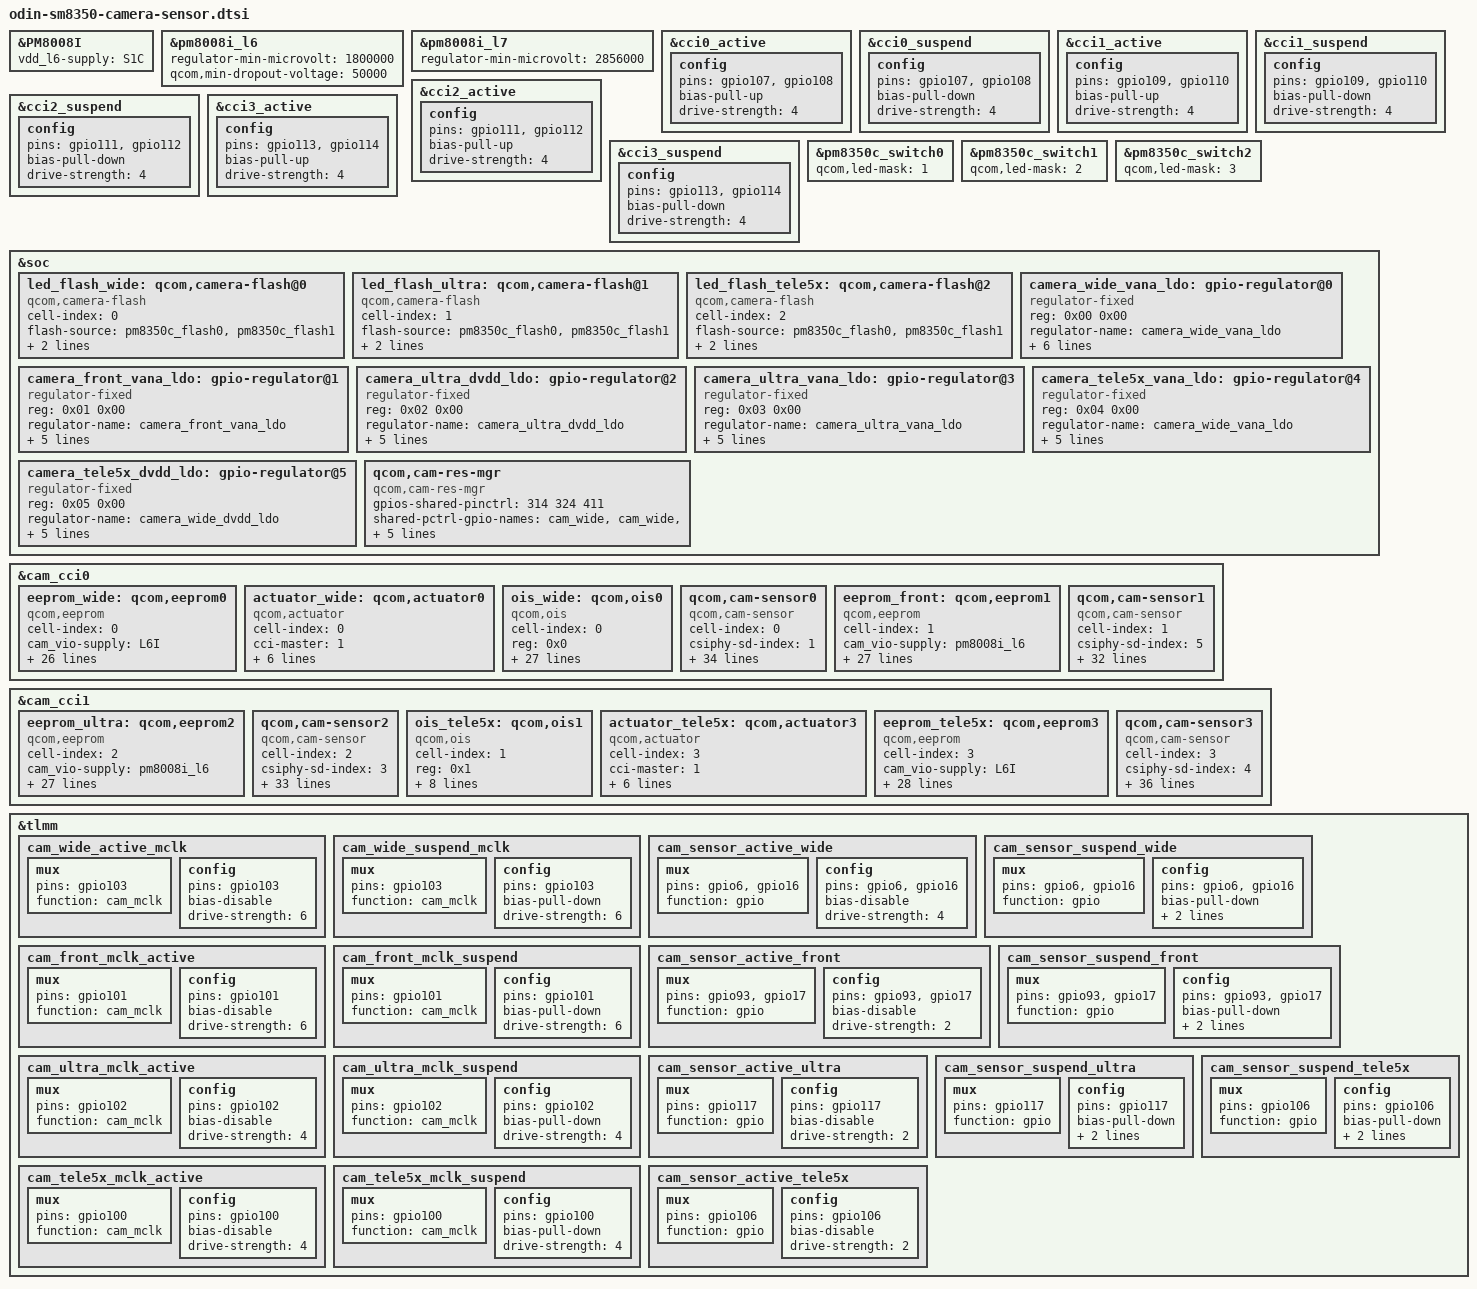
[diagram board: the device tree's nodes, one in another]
#include <dt-bindings/clock/qcom,camcc-lahaina.h>

&PM8008I {
	vdd_l6-supply = <&S1C>;
};

&pm8008i_l6 {
	regulator-min-microvolt = <1800000>;
	qcom,min-dropout-voltage = <50000>;
};

&pm8008i_l7 {
	regulator-min-microvolt = <2856000>;
};

&cci0_active {
	config {
		pins = "gpio107","gpio108";
		bias-pull-up; /* PULL UP*/
		drive-strength = <4>; /* 4 MA */
	};
};

&cci0_suspend {
	config {
		pins = "gpio107","gpio108";
		bias-pull-down; /* PULL DOWN */
		drive-strength = <4>; /* 4 MA */
	};
};

&cci1_active {
	config {
		pins = "gpio109","gpio110";
		bias-pull-up; /* PULL UP*/
		drive-strength = <4>; /* 4 MA */
	};
};

&cci1_suspend {
	config {
		pins = "gpio109","gpio110";
		bias-pull-down; /* PULL DOWN */
		drive-strength = <4>; /* 4 MA */
	};
};

&cci2_active {
	config {
		pins = "gpio111","gpio112";
		bias-pull-up; /* PULL UP*/
		drive-strength = <4>; /* 4 MA */
	};
};

&cci2_suspend {
	config {
		pins = "gpio111","gpio112";
		bias-pull-down; /* PULL DOWN */
		drive-strength = <4>; /* 4 MA */
	};
};

&cci3_active {
	config {
		pins = "gpio113","gpio114";
		bias-pull-up; /* PULL UP*/
		drive-strength = <4>; /* 4 MA */
	};
};

&cci3_suspend {
	config {
		pins = "gpio113","gpio114";
		bias-pull-down; /* PULL DOWN */
		drive-strength = <4>; /* 4 MA */
	};
};

&pm8350c_switch0 {
	qcom,led-mask = <1>; /* Channels 1*/
};

&pm8350c_switch1 {
	qcom,led-mask = <2>; /* Channels 2*/
};

&pm8350c_switch2 {
	qcom,led-mask = <3>; /* Channels 1&2*/
};

&soc {
	led_flash_wide: qcom,camera-flash@0 {
		cell-index = <0>;
		compatible = "qcom,camera-flash";
		flash-source = <&pm8350c_flash0 &pm8350c_flash1>;
		torch-source = <&pm8350c_torch0 &pm8350c_torch1>;
		switch-source = <&pm8350c_switch2>;
		status = "ok";
	};

	led_flash_ultra: qcom,camera-flash@1 {
		cell-index = <1>;
		compatible = "qcom,camera-flash";
		flash-source = <&pm8350c_flash0 &pm8350c_flash1>;
		torch-source = <&pm8350c_torch0 &pm8350c_torch1>;
		switch-source = <&pm8350c_switch2>;
		status = "ok";
	};

	led_flash_tele5x: qcom,camera-flash@2 {
		cell-index = <2>;
		compatible = "qcom,camera-flash";
		flash-source = <&pm8350c_flash0 &pm8350c_flash1>;
		torch-source = <&pm8350c_torch0 &pm8350c_torch1>;
		switch-source = <&pm8350c_switch2>;
		status = "ok";
	};

	camera_wide_vana_ldo: gpio-regulator@0 {
		compatible = "regulator-fixed";
		reg = <0x00 0x00>;
		regulator-name = "camera_wide_vana_ldo";
		regulator-min-microvolt = <2800000>;
		regulator-max-microvolt = <2800000>;
		regulator-enable-ramp-delay = <135>;
		enable-active-high;
		gpio = <&tlmm 6 0>;
		vin-supply = <&pm8350c_bob>;
	};

	camera_front_vana_ldo: gpio-regulator@1 {
		compatible = "regulator-fixed";
		reg = <0x01 0x00>;
		regulator-name = "camera_front_vana_ldo";
		regulator-min-microvolt = <2800000>;
		regulator-max-microvolt = <2800000>;
		regulator-enable-ramp-delay = <135>;
		enable-active-high;
		gpio = <&tlmm 93 0>;
	};

	camera_ultra_dvdd_ldo: gpio-regulator@2 {
		compatible = "regulator-fixed";
		reg = <0x02 0x00>;
		regulator-name = "camera_ultra_dvdd_ldo";
		regulator-min-microvolt = <1200000>;
		regulator-max-microvolt = <1200000>;
		regulator-enable-ramp-delay = <135>;
		enable-active-high;
		gpio = <&tlmm 74 0>;
	};


	camera_ultra_vana_ldo: gpio-regulator@3 {
		compatible = "regulator-fixed";
		reg = <0x03 0x00>;
		regulator-name = "camera_ultra_vana_ldo";
		regulator-min-microvolt = <2800000>;
		regulator-max-microvolt = <2800000>;
		regulator-enable-ramp-delay = <135>;
		enable-active-high;
		gpio = <&tlmm 66 0>;
	};

	camera_tele5x_vana_ldo: gpio-regulator@4 {
		compatible = "regulator-fixed";
		reg = <0x04 0x00>;
		regulator-name = "camera_wide_vana_ldo";
		regulator-min-microvolt = <2800000>;
		regulator-max-microvolt = <2800000>;
		regulator-enable-ramp-delay = <135>;
		enable-active-high;
		gpio = <&tlmm 34 0>;
	};

	camera_tele5x_dvdd_ldo: gpio-regulator@5 {
		compatible = "regulator-fixed";
		reg = <0x05 0x00>;
		regulator-name = "camera_wide_dvdd_ldo";
		regulator-min-microvolt = <1200000>;
		regulator-max-microvolt = <1200000>;
		regulator-enable-ramp-delay = <135>;
		enable-active-high;
		gpio = <&tlmm 74 0>;
	};

	qcom,cam-res-mgr {
		compatible = "qcom,cam-res-mgr";
		gpios-shared-pinctrl = <314 324 411>;
		shared-pctrl-gpio-names = "cam_wide", "cam_wide", "cam_wide";
		pinctrl-names = "cam_wide_active", "cam_wide_suspend";
		pinctrl-0 = <&cam_sensor_active_wide
		 		&cam_wide_active_mclk>;
		pinctrl-1 = <&cam_sensor_suspend_wide
		 		&cam_wide_suspend_mclk>;
		status = "ok";
	};
};

&cam_cci0 {
	// wide OV48B 48M
	eeprom_wide: qcom,eeprom0 {
		cell-index = <0>;
		compatible = "qcom,eeprom";
		cam_vio-supply = <&L6I>;
		cam_vaf-supply = <&L4I>;
		cam_v_custom1-supply = <&L3I>;
		cam_vdig-supply = <&L2I>;
		cam_vana-supply = <&camera_wide_vana_ldo>;
		cam_clk-supply = <&cam_cc_titan_top_gdsc>;
		cam_bob-supply = <&pm8350c_bob>;
		regulator-names = "cam_vio", "cam_vdig", "cam_vana", "cam_vaf","cam_v_custom1","cam_clk", "cam_bob";
		rgltr-cntrl-support;
		rgltr-min-voltage = <1800000 1104000 2800000 2800000 2800000 0 3200000>;
		rgltr-max-voltage = <1800000 1104000 2800000 2800000 2800000 0 3960000>;
		rgltr-load-current = <10000 140000 280000 100000 100000 0 2000000>;
		use-shared-clk;
		gpio-no-mux = <0>;
		gpios = <&tlmm 103 0>,
			<&tlmm 16 0>;
		gpio-reset = <1>;
		gpio-req-tbl-num = <0 1>;
		gpio-req-tbl-flags = <1 0>;
		gpio-req-tbl-label = "CAMIF_MCLK3",
					"CAM_RESET1";
		cci-master = <1>;
		clocks = <&clock_camcc CAM_CC_MCLK3_CLK>;
		clock-names = "cam_clk";
		clock-cntl-level = "nominal";
		clock-rates = <19200000>;
		status = "ok";
	};

	actuator_wide: qcom,actuator0 {
		cell-index = <0>;
		compatible = "qcom,actuator";
		cci-master = <1>;
		cam_vaf-supply = <&L4I>;
		regulator-names ="cam_vaf";
		rgltr-cntrl-support;
		rgltr-min-voltage = <2800000>;
		rgltr-max-voltage = <2800000>;
		rgltr-load-current = <100000>;
		status = "ok";
	};

	ois_wide: qcom,ois0 {
		cell-index = <0>;
		reg = <0x0>;
		compatible = "qcom,ois";
		cam_vio-supply = <&L6I>;
		cam_vaf-supply = <&L4I>;
		cam_v_custom1-supply = <&L3I>;
		cam_vdig-supply = <&L2I>;
		cam_vana-supply = <&camera_wide_vana_ldo>;
		cam_bob-supply = <&pm8350c_bob>;
		cam_clk-supply = <&cam_cc_titan_top_gdsc>;
		regulator-names = "cam_vio", "cam_vdig", "cam_vana", "cam_vaf","cam_v_custom1","cam_clk", "cam_bob";
		rgltr-cntrl-support;
		rgltr-min-voltage = <1800000 1104000 2800000 2800000 2800000 0 3200000>;
		rgltr-max-voltage = <1800000 1104000 2800000 2800000 2800000 0 3960000>;
		rgltr-load-current = <10000 140000 2800000 100000 10000 0 2000000>;
		use-shared-clk;
		gpio-no-mux = <0>;
		gpios = <&tlmm 103 0>,
			<&tlmm 16 0>;
		gpio-reset = <1>;
		gpio-req-tbl-num = <0 1>;
		gpio-req-tbl-flags = <1 0>;
		gpio-req-tbl-label = "CAMIF_MCLK3",
					"CAM_RESET1";
		cci-master = <1>;
		clocks = <&clock_camcc CAM_CC_MCLK3_CLK>;
		clock-names = "cam_clk";
		clock-cntl-level = "nominal";
		clock-rates = <19200000>;
		status = "ok";
	};

	qcom,cam-sensor0 {
		cell-index = <0>;
		compatible = "qcom,cam-sensor";
		csiphy-sd-index = <1>;
		sensor-position-roll = <90>;
		sensor-position-pitch = <0>;
		sensor-position-yaw = <180>;
		eeprom-src = <&eeprom_wide>;
		actuator-src = <&actuator_wide>;
		ois-src = <&ois_wide>;
		led-flash-src = <&led_flash_wide>;
		cam_vio-supply = <&L6I>;
		cam_vaf-supply = <&L4I>;
		cam_v_custom1-supply = <&L3I>;
		cam_vdig-supply = <&L2I>;
		cam_vana-supply = <&camera_wide_vana_ldo>;
		cam_clk-supply = <&cam_cc_titan_top_gdsc>;
		cam_bob-supply = <&pm8350c_bob>;
		regulator-names = "cam_vio", "cam_vdig", "cam_vana", "cam_vaf","cam_v_custom1","cam_clk", "cam_bob";
		rgltr-cntrl-support;
		rgltr-min-voltage = <1800000 1104000 2800000 2800000 2800000 0 3200000>;
		rgltr-max-voltage = <1800000 1104000 2800000 2800000 2800000 0 3960000>;
		rgltr-load-current = <10000 140000 280000 100000 100000 0 2000000>;
		use-shared-clk;
		gpio-no-mux = <0>;
		gpios = <&tlmm 103 0>,
			<&tlmm 16 0>;
		gpio-reset = <1>;
		gpio-req-tbl-num = <0 1>;
		gpio-req-tbl-flags = <1 0>;
		gpio-req-tbl-label = "CAMIF_MCLK3",
					"CAM_RESET1";
		cci-master = <1>;
		clocks = <&clock_camcc CAM_CC_MCLK3_CLK>;
		clock-names = "cam_clk";
		clock-cntl-level = "nominal";
		clock-rates = <19200000>;
		status = "ok";
	};

	eeprom_front: qcom,eeprom1 {
		cell-index = <1>;
		compatible = "qcom,eeprom";
		cam_vio-supply = <&pm8008i_l6>;
		cam_vdig-supply = <&pm8008i_l1>;
		cam_vana-supply = <&camera_front_vana_ldo>;
		cam_clk-supply = <&cam_cc_titan_top_gdsc>;
		cam_bob-supply = <&pm8350c_bob>;
		regulator-names = "cam_vio", "cam_vdig", "cam_vana",
			"cam_clk", "cam_bob";
		rgltr-cntrl-support;
		rgltr-min-voltage = <1800000 1056000 2800000 0 3200000>;
		rgltr-max-voltage = <1800000 1056000 2800000 0 3960000>;
		rgltr-load-current = <10000 140000 280000 0 2000000>;
		gpio-no-mux = <0>;
		pinctrl-names = "cam_default", "cam_suspend";
		pinctrl-0 = <&cam_sensor_active_front
			&cam_front_mclk_active>;
		pinctrl-1 = <&cam_sensor_suspend_front
			&cam_front_mclk_suspend>;
		gpios = <&tlmm 101 0>,
			<&tlmm 17 0>;
		gpio-reset = <1>;
		gpio-req-tbl-num = <0 1>;
		gpio-req-tbl-flags = <1 0>;
		gpio-req-tbl-label = "CAMIF_MCLK1",
					"CAM_RESET5";
		cci-master = <0>;
		clocks = <&clock_camcc CAM_CC_MCLK1_CLK>;
		clock-names = "cam_clk";
		clock-cntl-level = "nominal";
		clock-rates = <19200000>;
		status = "ok";
	};

	// Front 20M
	qcom,cam-sensor1 {
		cell-index = <1>;
		compatible = "qcom,cam-sensor";
		csiphy-sd-index = <5>;
		sensor-position-roll = <270>;
		sensor-position-pitch = <0>;
		sensor-position-yaw = <0>;
		eeprom-src = <&eeprom_front>;
		cam_vio-supply = <&pm8008i_l6>;
		cam_vdig-supply = <&pm8008i_l1>;
		cam_vana-supply = <&camera_front_vana_ldo>;
		cam_clk-supply = <&cam_cc_titan_top_gdsc>;
		cam_bob-supply = <&pm8350c_bob>;
		regulator-names = "cam_vio", "cam_vdig", "cam_vana",
			"cam_clk", "cam_bob";
		rgltr-cntrl-support;
		rgltr-min-voltage = <1800000 1056000 2800000 0 3200000>;
		rgltr-max-voltage = <1800000 1056000 2800000 0 3960000>;
		rgltr-load-current = <10000 140000 280000 0 2000000>;
		gpio-no-mux = <0>;
		pinctrl-names = "cam_default", "cam_suspend";
		pinctrl-0 = <&cam_sensor_active_front
			&cam_front_mclk_active>;
		pinctrl-1 = <&cam_sensor_suspend_front
			&cam_front_mclk_suspend>;
		gpios = <&tlmm 101 0>,
			<&tlmm 17 0>;
		gpio-reset = <1>;
		gpio-req-tbl-num = <0 1>;
		gpio-req-tbl-flags = <1 0>;
		gpio-req-tbl-label = "CAMIF_MCLK1",
					"CAM_RESET5";
		cci-master = <0>;
		clocks = <&clock_camcc CAM_CC_MCLK1_CLK>;
		clock-names = "cam_clk";
		clock-cntl-level = "nominal";
		clock-rates = <19200000>;
		status = "ok";
	};
};

&cam_cci1 {
	eeprom_ultra: qcom,eeprom2 {
		cell-index = <2>;
		compatible = "qcom,eeprom";
		cam_vio-supply = <&pm8008i_l6>;
		cam_vdig-supply = <&camera_ultra_dvdd_ldo>;
		cam_vana-supply = <&camera_ultra_vana_ldo>;
		cam_clk-supply = <&cam_cc_titan_top_gdsc>;
		cam_bob-supply = <&pm8350c_bob>;
		regulator-names = "cam_vio", "cam_vdig", "cam_vana", "cam_clk", "cam_bob";
		rgltr-cntrl-support;
		rgltr-min-voltage = <1800000 1200000 2800000 0 3200000>;
		rgltr-max-voltage = <1800000 1200000 2800000 0 3960000>;
		rgltr-load-current = <10000 140000 180000 0 2000000>;
		gpio-no-mux = <0>;
		pinctrl-names = "cam_default", "cam_suspend";
		pinctrl-0 = <&cam_sensor_active_ultra
				&cam_ultra_mclk_active>;
		pinctrl-1 = <&cam_sensor_suspend_ultra
				&cam_ultra_mclk_suspend>;
		gpios = <&tlmm 102 0>,
			<&tlmm 117 0>;
		gpio-reset = <1>;
		gpio-req-tbl-num = <0 1>;
		gpio-req-tbl-flags = <1 0>;
		gpio-req-tbl-label = "CAMIF_MCLK2",
					"CAM_RESET3";
		cci-master = <0>;
		clocks = <&clock_camcc CAM_CC_MCLK2_CLK>;
		clock-names = "cam_clk";
		clock-cntl-level = "nominal";
		clock-rates = <19200000>;
		status = "ok";
	};

	// Ultra 13M
	qcom,cam-sensor2 {
		cell-index = <2>;
		compatible = "qcom,cam-sensor";
		csiphy-sd-index = <3>;
		sensor-position-roll = <90>;
		sensor-position-pitch = <0>;
		sensor-position-yaw = <180>;
		eeprom-src = <&eeprom_ultra>;
		led-flash-src = <&led_flash_ultra>;
		cam_vio-supply = <&pm8008i_l6>;
		cam_vdig-supply = <&camera_ultra_dvdd_ldo>;
		cam_vana-supply = <&camera_ultra_vana_ldo>;
		cam_clk-supply = <&cam_cc_titan_top_gdsc>;
		cam_bob-supply = <&pm8350c_bob>;
		regulator-names = "cam_vio", "cam_vdig", "cam_vana", "cam_clk", "cam_bob";
		rgltr-cntrl-support;
		rgltr-min-voltage = <1800000 1200000 2800000 0 3200000>;
		rgltr-max-voltage = <1800000 1200000 2800000 0 3960000>;
		rgltr-load-current = <10000 140000 180000 0 2000000>;
		gpio-no-mux = <0>;
		pinctrl-names = "cam_default", "cam_suspend";
		pinctrl-0 = <&cam_sensor_active_ultra
				&cam_ultra_mclk_active>;
		pinctrl-1 = <&cam_sensor_suspend_ultra
				&cam_ultra_mclk_suspend>;
		gpios = <&tlmm 102 0>,
			<&tlmm 117 0>;
		gpio-reset = <1>;
		gpio-req-tbl-num = <0 1>;
		gpio-req-tbl-flags = <1 0>;
		gpio-req-tbl-label = "CAMIF_MCLK2",
					"CAM_RESET3";
		cci-master = <0>;
		clocks = <&clock_camcc CAM_CC_MCLK2_CLK>;
		clock-names = "cam_clk";
		clock-cntl-level = "nominal";
		clock-rates = <19200000>;
		status = "ok";
	};
	ois_tele5x: qcom,ois1 {
		cell-index = <1>;
		reg = <0x1>;
		compatible = "qcom,ois";
		cam_vio-supply = <&L6I>;
		cam_vaf-supply = <&L7I>;
		regulator-names = "cam_vio", "cam_vaf";
		rgltr-min-voltage = <1800000 2856000>;
		rgltr-max-voltage = <1800000 2856000>;
		rgltr-load-current = <10000 300000>;
		rgltr-cntrl-support;
		cci-master = <1>;
		status = "ok";
	};

	actuator_tele5x: qcom,actuator3 {
		cell-index = <3>;
		compatible = "qcom,actuator";
		cci-master = <1>;
		cam_vaf-supply = <&L7I>;
		regulator-names = "cam_vaf";
		rgltr-cntrl-support;
		rgltr-min-voltage = <2856000>;
		rgltr-max-voltage = <2856000>;
		rgltr-load-current = <300000>;
		status = "ok";
	};

	eeprom_tele5x: qcom,eeprom3 {
		cell-index = <3>;
		compatible = "qcom,eeprom";
		cam_vio-supply = <&L6I>;
		cam_vdig-supply = <&camera_tele5x_dvdd_ldo>;
		cam_vana-supply = <&camera_tele5x_vana_ldo>;
		cam_vaf-supply = <&L7I>;
		cam_clk-supply = <&cam_cc_titan_top_gdsc>;
		cam_bob-supply = <&pm8350c_bob>;
		regulator-names = "cam_vio", "cam_vdig", "cam_vana","cam_vaf","cam_clk", "cam_bob";
		rgltr-cntrl-support;
		rgltr-min-voltage = <1800000 1200000 2800000 2856000 0 3200000>;
		rgltr-max-voltage = <1800000 1200000 2800000 2856000 0 3960000>;
		rgltr-load-current = <10000 140000 180000 296000 0 2000000>;
		gpio-no-mux = <0>;
		pinctrl-names = "cam_default", "cam_suspend";
		pinctrl-0 = <&cam_sensor_active_tele5x
				&cam_tele5x_mclk_active>;
		pinctrl-1 = <&cam_sensor_suspend_tele5x
				&cam_tele5x_mclk_suspend>;
		gpios = <&tlmm 100 0>,
			<&tlmm 106 0>;
		gpio-reset = <1>;
		gpio-req-tbl-num = <0 1>;
		gpio-req-tbl-flags = <1 0>;
		gpio-req-tbl-label = "CAMIF_MCLK0",
					"CAM_RESET4";
		cci-master = <1>;
		clocks = <&clock_camcc CAM_CC_MCLK0_CLK>;
		clock-names = "cam_clk";
		clock-cntl-level = "nominal";
		clock-rates = <19200000>;
		status = "ok";
	};

	// Folded 8M
	qcom,cam-sensor3 {
		cell-index = <3>;
		compatible = "qcom,cam-sensor";
		csiphy-sd-index = <4>;
		sensor-position-roll = <90>;
		sensor-position-pitch = <0>;
		sensor-position-yaw = <180>;
		eeprom-src = <&eeprom_tele5x>;
		led-flash-src = <&led_flash_tele5x>;
		actuator-src = <&actuator_tele5x>;
		ois-src = <&ois_tele5x>;
		cam_vio-supply = <&L6I>;
		cam_vdig-supply = <&camera_tele5x_dvdd_ldo>;
		cam_vana-supply = <&camera_tele5x_vana_ldo>;
		cam_vaf-supply = <&L7I>;
		cam_clk-supply = <&cam_cc_titan_top_gdsc>;
		cam_bob-supply = <&pm8350c_bob>;
		regulator-names = "cam_vio", "cam_vdig", "cam_vana","cam_vaf", "cam_clk", "cam_bob";
		rgltr-cntrl-support;
		rgltr-min-voltage = <1800000 1200000 2800000 2856000 0 3200000>;
		rgltr-max-voltage = <1800000 1200000 2800000 2856000 0 3960000>;
		rgltr-load-current = <10000 140000 280000 296000 0 2000000>;
		gpio-no-mux = <0>;
		pinctrl-names = "cam_default", "cam_suspend";
		pinctrl-0 = <&cam_sensor_active_tele5x
				&cam_tele5x_mclk_active>;
		pinctrl-1 = <&cam_sensor_suspend_tele5x
				&cam_tele5x_mclk_suspend>;
		gpios = <&tlmm 100 0>,
			<&tlmm 106 0>;
		gpio-reset = <1>;
		gpio-req-tbl-num = <0 1>;
		gpio-req-tbl-flags = <1 0>;
		gpio-req-tbl-label = "CAMIF_MCLK0",
					"CAM_RESET4";
		cci-master = <1>;
		clocks = <&clock_camcc CAM_CC_MCLK0_CLK>;
		clock-names = "cam_clk";
		clock-cntl-level = "nominal";
		clock-rates = <19200000>;
		status = "ok";
	};
};

&tlmm {
	cam_wide_active_mclk: cam_wide_active_mclk {
			mux {
					pins = "gpio103";
					function = "cam_mclk";
			};

			config {
					pins = "gpio103";
					bias-disable; /* No PULL */
					drive-strength = <6>; /* 6 MA */
			};
	};

	cam_wide_suspend_mclk: cam_wide_suspend_mclk {
			mux {
					pins = "gpio103";
					function = "cam_mclk";
			};

			config {
					pins = "gpio103";
					bias-pull-down; /* PULL DOWN */
					drive-strength = <6>; /* 6 MA */
			};
	};

	cam_sensor_active_wide: cam_sensor_active_wide {
		mux {
			pins = "gpio6", "gpio16";
			function = "gpio";
		};

		config {
			pins = "gpio6", "gpio16";
			bias-disable; /* No PULL */
			drive-strength = <4>; /* 4 MA */
		};
	};

	cam_sensor_suspend_wide: cam_sensor_suspend_wide {
		mux {
			pins = "gpio6", "gpio16";
			function = "gpio";
		};

		config {
			pins = "gpio6", "gpio16";
			bias-pull-down; /* PULL DOWN */
			drive-strength = <4>; /* 4 MA */
			output-low;
		};
	};

	cam_front_mclk_active: cam_front_mclk_active {
		mux {
			pins = "gpio101";
			function = "cam_mclk";
		};

		config {
			pins = "gpio101";
			bias-disable; /* No PULL */
			drive-strength = <6>; /* 6 MA */
		};
	};

	cam_front_mclk_suspend: cam_front_mclk_suspend {
		mux {
			pins = "gpio101";
			function = "cam_mclk";
		};

		config {
			pins = "gpio101";
			bias-pull-down; /* PULL DOWN */
			drive-strength = <6>; /* 6 MA */
		};
	};

	cam_sensor_active_front: cam_sensor_active_front {
		/*AVDD RESET */
		mux {
			pins = "gpio93", "gpio17";
			function = "gpio";
		};

		config {
			pins = "gpio93", "gpio17";
			bias-disable; /* No PULL */
			drive-strength = <2>; /* 2 MA */
		};
	};

	cam_sensor_suspend_front: cam_sensor_suspend_front {
		mux {
			pins = "gpio93", "gpio17";
			function = "gpio";
		};

		config {
			pins = "gpio93", "gpio17";
			bias-pull-down; /* PULL DOWN */
			drive-strength = <2>; /* 2 MA */
			output-low;
		};
	};

	cam_ultra_mclk_active: cam_ultra_mclk_active {
		mux {
			pins = "gpio102";
			function = "cam_mclk";
		};

		config {
			pins = "gpio102";
			bias-disable; /* No PULL */
			drive-strength = <4>; /* 4 MA */
		};
	};

	cam_ultra_mclk_suspend: cam_ultra_mclk_suspend {
		mux {
			pins = "gpio102";
			function = "cam_mclk";
		};

		config {
			pins = "gpio102";
			bias-pull-down; /* PULL DOWN */
			drive-strength = <4>; /* 4 MA */
		};
	};

	cam_sensor_active_ultra: cam_sensor_active_ultra {
		/*RESET */
		mux {
			pins = "gpio117";
			function = "gpio";
		};

		config {
			pins = "gpio117";
			bias-disable; /* No PULL */
			drive-strength = <2>; /* 2 MA */
		};
	};

	cam_sensor_suspend_ultra: cam_sensor_suspend_ultra {
		mux {
			pins = "gpio117";
			function = "gpio";
		};

		config {
			pins = "gpio117";
			bias-pull-down; /* PULL DOWN */
			drive-strength = <2>; /* 2 MA */
			output-low;
		};
	};

	cam_tele5x_mclk_active: cam_tele5x_mclk_active {
		mux {
			pins = "gpio100";
			function = "cam_mclk";
		};

		config {
			pins = "gpio100";
			bias-disable; /* No PULL */
			drive-strength = <4>; /* 4 MA */
		};
	};

	cam_tele5x_mclk_suspend: cam_tele5x_mclk_suspend {
		mux {
			pins = "gpio100";
			function = "cam_mclk";
		};

		config {
			pins = "gpio100";
			bias-pull-down; /* PULL DOWN */
			drive-strength = <4>; /* 4 MA */
		};
	};

	cam_sensor_active_tele5x: cam_sensor_active_tele5x {
		/*RESET */
		mux {
			pins = "gpio106";
			function = "gpio";
		};

		config {
			pins = "gpio106";
			bias-disable; /* No PULL */
			drive-strength = <2>; /* 2 MA */
		};
	};

	cam_sensor_suspend_tele5x: cam_sensor_suspend_tele5x {
		mux {
			pins = "gpio106";
			function = "gpio";
		};

		config {
			pins = "gpio106";
			bias-pull-down; /* PULL DOWN */
			drive-strength = <2>; /* 2 MA */
			output-low;
		};
	};
};

